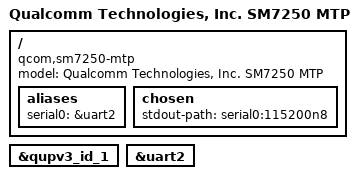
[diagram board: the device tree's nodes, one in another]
// SPDX-License-Identifier: BSD-3-Clause
/*
 * Copyright (c) 2020, The Linux Foundation. All rights reserved.
 * Copyright (c) 2026, Sreeshankar K <sreeshankar0910@gmail.com>
 */

/dts-v1/;

#include "sm7250.dtsi"

/ {
	model = "Qualcomm Technologies, Inc. SM7250 MTP";
	compatible = "qcom,sm7250-mtp", "qcom,sm7250";

	aliases {
		serial0 = &uart2;
	};

	chosen {
		stdout-path = "serial0:115200n8";
	};
};

&qupv3_id_1 {
	status = "okay";
};

&uart2 {
	status = "okay";
};
